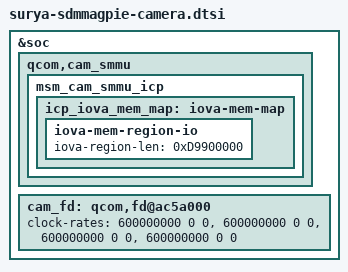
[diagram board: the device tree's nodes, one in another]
&soc {
	qcom,cam_smmu {
		msm_cam_smmu_icp {
			icp_iova_mem_map: iova-mem-map {
				iova-mem-region-io {
					iova-region-len = <0xD9900000>;
                };
            };
        };
    };
	cam_fd: qcom,fd@ac5a000 {
		clock-rates =
			<600000000 0 0>,
			<600000000 0 0>,
			<600000000 0 0>,
			<600000000 0 0>;
	};
};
